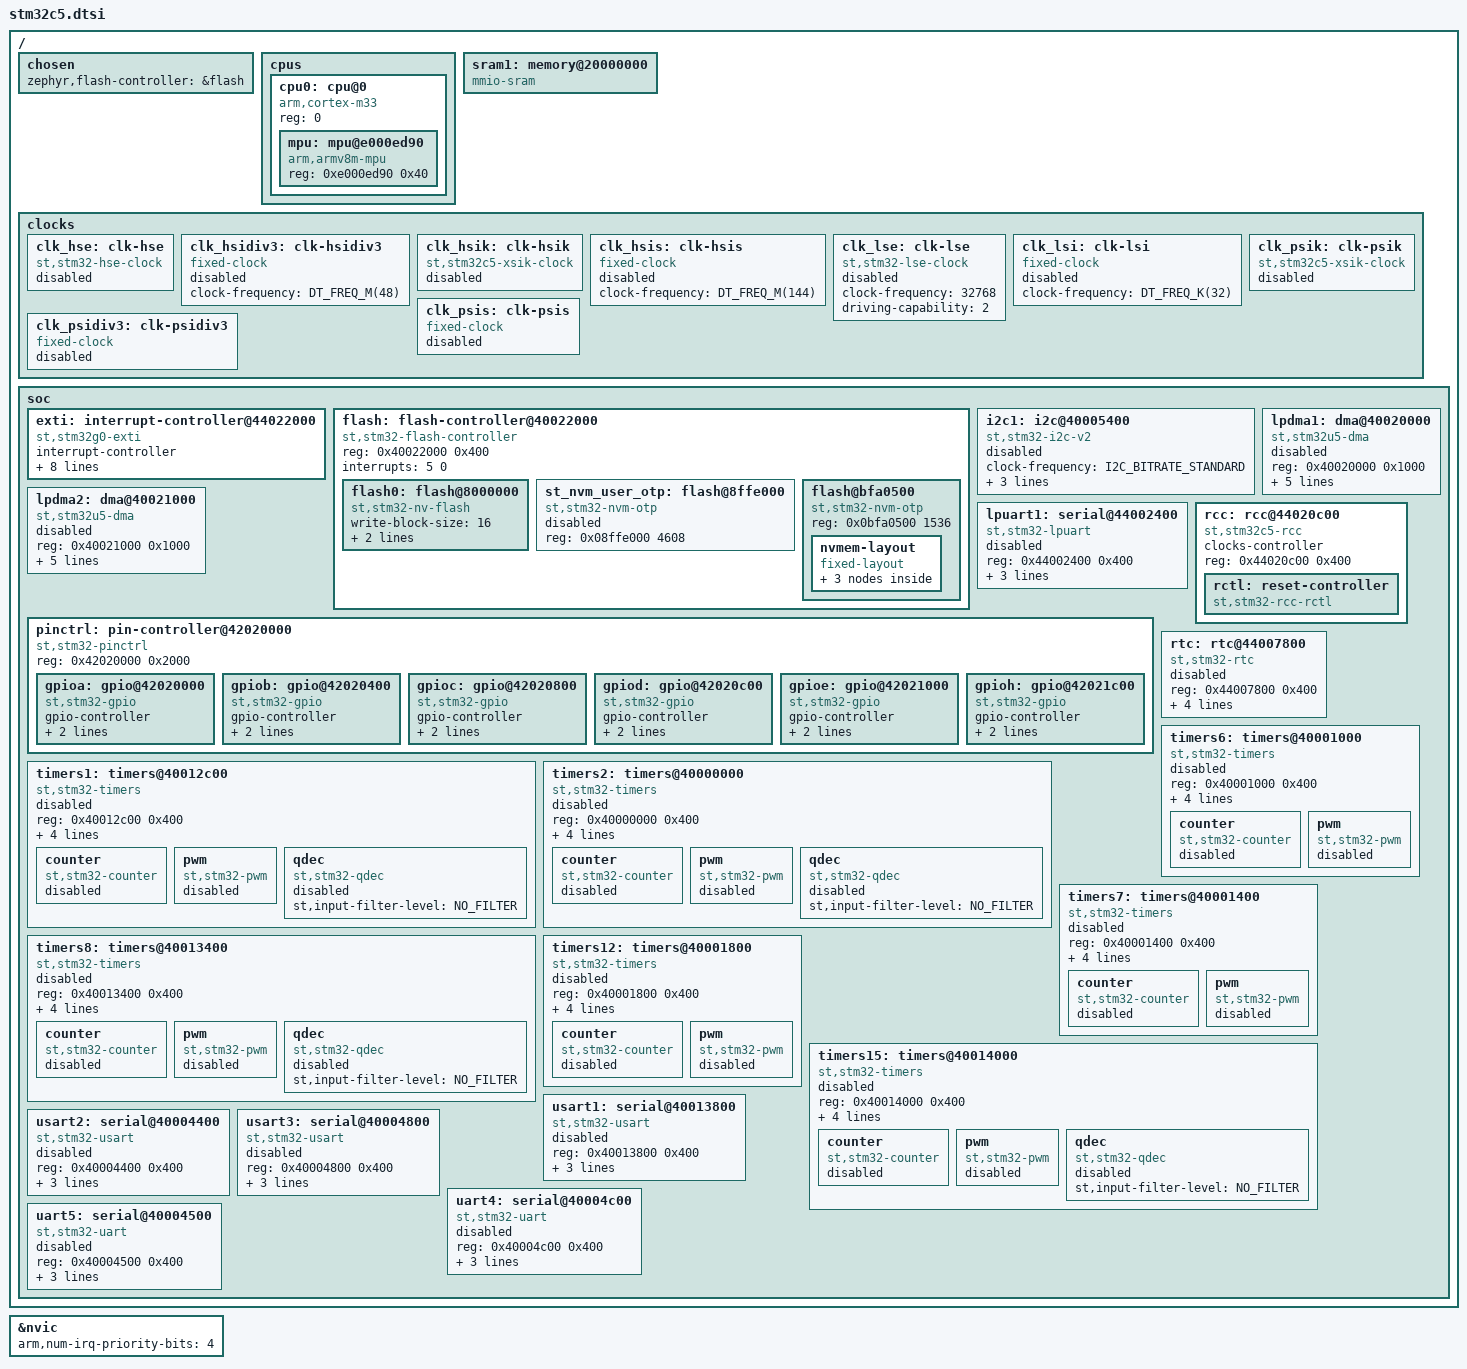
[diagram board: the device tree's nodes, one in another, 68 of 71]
/*
 * Copyright (c) 2026 STMicroelectronics
 *
 * SPDX-License-Identifier: Apache-2.0
 */

#include <arm/armv8-m.dtsi>
#include <zephyr/dt-bindings/clock/stm32c5_clock.h>
#include <zephyr/dt-bindings/dma/stm32_dma.h>
#include <zephyr/dt-bindings/gpio/gpio.h>
#include <zephyr/dt-bindings/i2c/i2c.h>
#include <zephyr/dt-bindings/reset/stm32c5_reset.h>
#include <zephyr/dt-bindings/sensor/qdec_stm32.h>
#include <freq.h>

/ {
	chosen {
		zephyr,flash-controller = &flash;
	};

	cpus {
		#address-cells = <1>;
		#size-cells = <0>;

		cpu0: cpu@0 {
			device_type = "cpu";
			compatible = "arm,cortex-m33";
			reg = <0>;
			#address-cells = <1>;
			#size-cells = <1>;

			mpu: mpu@e000ed90 {
				compatible = "arm,armv8m-mpu";
				reg = <0xe000ed90 0x40>;
			};
		};
	};

	sram1: memory@20000000 {
		compatible = "mmio-sram";
	};

	clocks {
		clk_hse: clk-hse {
			#clock-cells = <0>;
			compatible = "st,stm32-hse-clock";
			status = "disabled";
		};

		clk_hsidiv3: clk-hsidiv3 {
			#clock-cells = <0>;
			compatible = "fixed-clock";
			clock-frequency = <DT_FREQ_M(48)>;
			status = "disabled";
		};

		clk_hsik: clk-hsik {
			#clock-cells = <0>;
			compatible = "st,stm32c5-xsik-clock";
			status = "disabled";
		};

		clk_hsis: clk-hsis {
			#clock-cells = <0>;
			compatible = "fixed-clock";
			clock-frequency = <DT_FREQ_M(144)>;
			status = "disabled";
		};

		clk_lse: clk-lse {
			#clock-cells = <0>;
			compatible = "st,stm32-lse-clock";
			clock-frequency = <32768>;
			driving-capability = <2>;
			status = "disabled";
		};

		clk_lsi: clk-lsi {
			#clock-cells = <0>;
			compatible = "fixed-clock";
			clock-frequency = <DT_FREQ_K(32)>;
			status = "disabled";
		};

		clk_psidiv3: clk-psidiv3 {
			#clock-cells = <0>;
			compatible = "fixed-clock";
			status = "disabled";
		};

		clk_psik: clk-psik {
			#clock-cells = <0>;
			compatible = "st,stm32c5-xsik-clock";
			status = "disabled";
		};

		clk_psis: clk-psis {
			#clock-cells = <0>;
			compatible = "fixed-clock";
			status = "disabled";
		};
	};

	soc {
		exti: interrupt-controller@44022000 {
			compatible = "st,stm32g0-exti", "st,stm32-exti";
			interrupt-controller;
			#interrupt-cells = <1>;
			#address-cells = <1>;
			reg = <0x44022000 0x400>;
			num-lines = <40>;
			interrupts = <7 0>, <8 0>, <9 0>, <10 0>,
				     <11 0>, <12 0>, <13 0>, <14 0>,
				     <15 0>, <16 0>, <17 0>, <18 0>,
				     <19 0>, <20 0>, <21 0>, <22 0>;
			interrupt-names = "line0", "line1", "line2", "line3",
					  "line4", "line5", "line6", "line7",
					  "line8", "line9", "line10", "line11",
					  "line12", "line13", "line14", "line15";
			line-ranges = <0 1>, <1 1>, <2 1>, <3 1>,
				      <4 1>, <5 1>, <6 1>, <7 1>,
				      <8 1>, <9 1>, <10 1>, <11 1>,
				      <12 1>, <13 1>, <14 1>, <15 1>;
		};

		flash: flash-controller@40022000 {
			compatible = "st,stm32-flash-controller", "st,stm32c5-flash-controller";
			reg = <0x40022000 0x400>;
			interrupts = <5 0>;

			#address-cells = <1>;
			#size-cells = <1>;

			flash0: flash@8000000 {
				compatible = "st,stm32-nv-flash", "soc-nv-flash";

				write-block-size = <16>;
				erase-block-size = <8192>;
				/* maximum erase time(ms) for a 8K sector */
				max-erase-time = <3>;
			};

			st_nvm_user_otp: flash@8ffe000 {
				compatible = "st,stm32-nvm-otp";
				reg = <0x08ffe000 4608>; /* 4.5KB */
				status = "disabled";
			};

			/* "FLASH read-only area" */
			flash@bfa0500 {
				compatible = "st,stm32-nvm-otp";
				reg = <0x0bfa0500 1536>; /* 1.5KB */

				nvmem-layout {
					compatible = "fixed-layout";
					#address-cells = <1>;
					#size-cells = <1>;

					vrefint_otp: vrefint@10 {
						reg = <0x10 0x2>;
						#nvmem-cell-cells = <0>;
						read-only;
					};

					ts_cal1_otp: ts-cal1@14 {
						reg = <0x14 0x2>;
						#nvmem-cell-cells = <0>;
						read-only;
					};

					ts_cal2_otp: ts-cal2@18 {
						reg = <0x18 0x2>;
						#nvmem-cell-cells = <0>;
						read-only;
					};
				};
			};
		};

		i2c1: i2c@40005400 {
			compatible = "st,stm32-i2c-v2";
			clock-frequency = <I2C_BITRATE_STANDARD>;
			#address-cells = <1>;
			#size-cells = <0>;
			reg = <0x40005400 0x400>;
			clocks = <&rcc STM32_CLOCK(APB1, 21)>;
			interrupts = <44 0>, <45 0>;
			interrupt-names = "event", "error";
			status = "disabled";
		};

		lpdma1: dma@40020000 {
			compatible = "st,stm32u5-dma";
			#dma-cells = <3>;
			reg = <0x40020000 0x1000>;
			clocks = <&rcc STM32_CLOCK(AHB1, 0)>;
			interrupts = <23 0>, <24 0>, <25 0>, <26 0>;
			dma-channels = <4>;
			dma-requests = <94>;
			dma-offset = <0>;
			status = "disabled";
		};

		lpdma2: dma@40021000 {
			compatible = "st,stm32u5-dma";
			#dma-cells = <3>;
			reg = <0x40021000 0x1000>;
			clocks = <&rcc STM32_CLOCK(AHB1, 1)>;
			interrupts = <78 0>, <79 0>, <80 0>, <81 0>;
			dma-channels = <4>;
			dma-requests = <94>;
			dma-offset = <0>;
			status = "disabled";
		};

		lpuart1: serial@44002400 {
			compatible = "st,stm32-lpuart", "st,stm32-uart";
			reg = <0x44002400 0x400>;
			clocks = <&rcc STM32_CLOCK(APB3, 6)>;
			resets = <&rctl STM32_RESET(APB3, 6)>;
			interrupts = <56 0>;
			status = "disabled";
		};

		pinctrl: pin-controller@42020000 {
			compatible = "st,stm32-pinctrl";
			#address-cells = <1>;
			#size-cells = <1>;
			reg = <0x42020000 0x2000>;

			gpioa: gpio@42020000 {
				compatible = "st,stm32-gpio";
				gpio-controller;
				#gpio-cells = <2>;
				reg = <0x42020000 0x400>;
				clocks = <&rcc STM32_CLOCK(AHB2, 0)>;
			};

			gpiob: gpio@42020400 {
				compatible = "st,stm32-gpio";
				gpio-controller;
				#gpio-cells = <2>;
				reg = <0x42020400 0x400>;
				clocks = <&rcc STM32_CLOCK(AHB2, 1)>;
			};

			gpioc: gpio@42020800 {
				compatible = "st,stm32-gpio";
				gpio-controller;
				#gpio-cells = <2>;
				reg = <0x42020800 0x400>;
				clocks = <&rcc STM32_CLOCK(AHB2, 2)>;
			};

			gpiod: gpio@42020c00 {
				compatible = "st,stm32-gpio";
				gpio-controller;
				#gpio-cells = <2>;
				reg = <0x42020c00 0x400>;
				clocks = <&rcc STM32_CLOCK(AHB2, 3)>;
			};

			gpioe: gpio@42021000 {
				compatible = "st,stm32-gpio";
				gpio-controller;
				#gpio-cells = <2>;
				reg = <0x42021000 0x400>;
				clocks = <&rcc STM32_CLOCK(AHB2, 4)>;
			};

			gpioh: gpio@42021c00 {
				compatible = "st,stm32-gpio";
				gpio-controller;
				#gpio-cells = <2>;
				reg = <0x42021c00 0x400>;
				clocks = <&rcc STM32_CLOCK(AHB2, 7)>;
			};
		};

		rcc: rcc@44020c00 {
			compatible = "st,stm32c5-rcc";
			clocks-controller;
			#clock-cells = <2>;
			reg = <0x44020c00 0x400>;

			rctl: reset-controller {
				compatible = "st,stm32-rcc-rctl";
				#reset-cells = <1>;
			};
		};

		rtc: rtc@44007800 {
			compatible = "st,stm32-rtc";
			reg = <0x44007800 0x400>;
			interrupts = <2 0>;
			clocks = <&rcc STM32_CLOCK(APB3, 21)>;
			prescaler = <32768>;
			alarms-count = <2>;
			status = "disabled";
		};

		timers1: timers@40012c00 {
			compatible = "st,stm32-timers";
			reg = <0x40012c00 0x400>;
			clocks = <&rcc STM32_CLOCK(APB2, 11)>,
				 <&rcc STM32_SRC_HCLK NO_SEL>;
			resets = <&rctl STM32_RESET(APB2, 11)>;
			interrupts = <36 0>, <37 0>, <38 0>, <39 0>;
			interrupt-names = "brk", "up", "trgcom", "cc";
			status = "disabled";

			counter {
				compatible = "st,stm32-counter";
				status = "disabled";
			};

			pwm {
				compatible = "st,stm32-pwm";
				status = "disabled";
				#pwm-cells = <3>;
			};

			qdec {
				compatible = "st,stm32-qdec";
				st,input-filter-level = <NO_FILTER>;
				status = "disabled";
			};
		};

		timers2: timers@40000000 {
			compatible = "st,stm32-timers";
			reg = <0x40000000 0x400>;
			clocks = <&rcc STM32_CLOCK(APB1, 0)>,
				 <&rcc STM32_SRC_HCLK NO_SEL>;
			resets = <&rctl STM32_RESET(APB1L, 0)>;
			interrupts = <40 0>;
			interrupt-names = "global";
			status = "disabled";

			counter {
				compatible = "st,stm32-counter";
				status = "disabled";
			};

			pwm {
				compatible = "st,stm32-pwm";
				status = "disabled";
				#pwm-cells = <3>;
			};

			qdec {
				compatible = "st,stm32-qdec";
				st,input-filter-level = <NO_FILTER>;
				status = "disabled";
			};
		};

		timers6: timers@40001000 {
			compatible = "st,stm32-timers";
			reg = <0x40001000 0x400>;
			clocks = <&rcc STM32_CLOCK(APB1, 4)>,
				 <&rcc STM32_SRC_HCLK NO_SEL>;
			resets = <&rctl STM32_RESET(APB1L, 4)>;
			interrupts = <42 0>;
			interrupt-names = "global";
			status = "disabled";

			counter {
				compatible = "st,stm32-counter";
				status = "disabled";
			};

			pwm {
				compatible = "st,stm32-pwm";
				status = "disabled";
				#pwm-cells = <3>;
			};
		};

		timers7: timers@40001400 {
			compatible = "st,stm32-timers";
			reg = <0x40001400 0x400>;
			clocks = <&rcc STM32_CLOCK(APB1, 5)>,
				 <&rcc STM32_SRC_HCLK NO_SEL>;
			resets = <&rctl STM32_RESET(APB1L, 5)>;
			interrupts = <43 0>;
			interrupt-names = "global";
			status = "disabled";

			counter {
				compatible = "st,stm32-counter";
				status = "disabled";
			};

			pwm {
				compatible = "st,stm32-pwm";
				status = "disabled";
				#pwm-cells = <3>;
			};
		};

		timers8: timers@40013400 {
			compatible = "st,stm32-timers";
			reg = <0x40013400 0x400>;
			clocks = <&rcc STM32_CLOCK(APB2, 13)>,
				 <&rcc STM32_SRC_HCLK NO_SEL>;
			resets = <&rctl STM32_RESET(APB2, 13)>;
			interrupts = <72 0>, <73 0>, <74 0>, <75 0>;
			interrupt-names = "brk", "up", "trgcom", "cc";
			status = "disabled";

			counter {
				compatible = "st,stm32-counter";
				status = "disabled";
			};

			pwm {
				compatible = "st,stm32-pwm";
				status = "disabled";
				#pwm-cells = <3>;
			};

			qdec {
				compatible = "st,stm32-qdec";
				st,input-filter-level = <NO_FILTER>;
				status = "disabled";
			};
		};

		timers12: timers@40001800 {
			compatible = "st,stm32-timers";
			reg = <0x40001800 0x400>;
			clocks = <&rcc STM32_CLOCK(APB1, 6)>,
				 <&rcc STM32_SRC_HCLK NO_SEL>;
			resets = <&rctl STM32_RESET(APB1L, 6)>;
			interrupts = <58 0>;
			interrupt-names = "global";
			status = "disabled";

			counter {
				compatible = "st,stm32-counter";
				status = "disabled";
			};

			pwm {
				compatible = "st,stm32-pwm";
				status = "disabled";
				#pwm-cells = <3>;
			};
		};

		timers15: timers@40014000 {
			compatible = "st,stm32-timers";
			reg = <0x40014000 0x400>;
			clocks = <&rcc STM32_CLOCK(APB2, 16)>,
				 <&rcc STM32_SRC_HCLK NO_SEL>;
			resets = <&rctl STM32_RESET(APB2, 16)>;
			interrupts = <59 0>;
			interrupt-names = "global";
			status = "disabled";

			counter {
				compatible = "st,stm32-counter";
				status = "disabled";
			};

			pwm {
				compatible = "st,stm32-pwm";
				status = "disabled";
				#pwm-cells = <3>;
			};

			qdec {
				compatible = "st,stm32-qdec";
				st,input-filter-level = <NO_FILTER>;
				status = "disabled";
			};
		};

		usart1: serial@40013800 {
			compatible = "st,stm32-usart", "st,stm32-uart";
			reg = <0x40013800 0x400>;
			clocks = <&rcc STM32_CLOCK(APB2, 14)>;
			resets = <&rctl STM32_RESET(APB2, 14)>;
			interrupts = <51 0>;
			status = "disabled";
		};

		usart2: serial@40004400 {
			compatible = "st,stm32-usart", "st,stm32-uart";
			reg = <0x40004400 0x400>;
			clocks = <&rcc STM32_CLOCK(APB1, 17)>;
			resets = <&rctl STM32_RESET(APB1L, 17)>;
			interrupts = <52 0>;
			status = "disabled";
		};

		usart3: serial@40004800 {
			compatible = "st,stm32-usart", "st,stm32-uart";
			reg = <0x40004800 0x400>;
			clocks = <&rcc STM32_CLOCK(APB1, 18)>;
			resets = <&rctl STM32_RESET(APB1L, 18)>;
			interrupts = <53 0>;
			status = "disabled";
		};

		uart4: serial@40004c00 {
			compatible = "st,stm32-uart";
			reg = <0x40004c00 0x400>;
			clocks = <&rcc STM32_CLOCK(APB1, 19)>;
			resets = <&rctl STM32_RESET(APB1L, 19)>;
			interrupts = <54 0>;
			status = "disabled";
		};

		uart5: serial@40004500 {
			compatible = "st,stm32-uart";
			reg = <0x40004500 0x400>;
			clocks = <&rcc STM32_CLOCK(APB1, 20)>;
			resets = <&rctl STM32_RESET(APB1L, 20)>;
			interrupts = <55 0>;
			status = "disabled";
		};
	};
};

&nvic {
	arm,num-irq-priority-bits = <4>;
};
